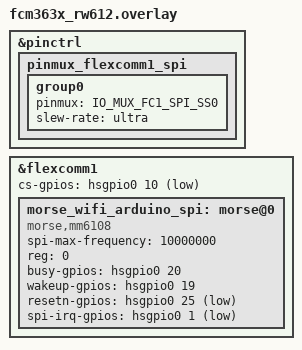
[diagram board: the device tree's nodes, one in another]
/*
 * Board-specific overlay to bind morse_mmech08 to fcm363x (rw612).
 * This replaces the Arduino-header assumptions in the generic shield overlay.
 */

&pinctrl {
  status = "okay";
  pinmux_flexcomm1_spi: pinmux_flexcomm1_spi {
    group0 {
      pinmux = <IO_MUX_FC1_SPI_SS0>;
      slew-rate = "ultra";
    };
  };
};

/* Pick the correct SPI controller for your wiring */
&flexcomm1 {
	status = "okay";

	cs-gpios = <&hsgpio0 10 GPIO_ACTIVE_LOW>;

	morse_wifi_arduino_spi: morse@0 {
		status = "okay";
		compatible = "morse,mm6108";
		spi-max-frequency = <10000000>;
		reg = <0>;

		/* Replace these with your actual GPIO wiring */
		busy-gpios    = <&hsgpio0 20 GPIO_ACTIVE_HIGH>;
		wakeup-gpios  = <&hsgpio0 19 GPIO_ACTIVE_HIGH>;
		resetn-gpios  = <&hsgpio0 25 GPIO_ACTIVE_LOW>;
		spi-irq-gpios = <&hsgpio0 1  GPIO_ACTIVE_LOW>;
	};
};
